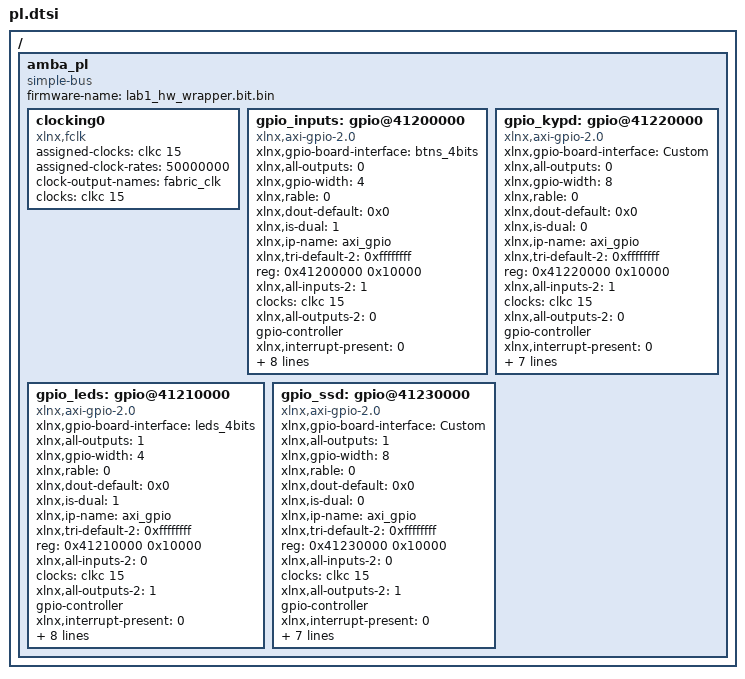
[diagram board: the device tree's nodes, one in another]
/ {
	amba_pl: amba_pl {
		ranges;
		compatible = "simple-bus";
		#address-cells = <1>;
		#size-cells = <1>;
		firmware-name = "lab1_hw_wrapper.bit.bin";
		clocking0: clocking0 {
			compatible = "xlnx,fclk";
			assigned-clocks = <&clkc 15>;
			assigned-clock-rates = <50000000>;
			#clock-cells = <0>;
			clock-output-names = "fabric_clk";
			clocks = <&clkc 15>;
		};
		gpio_inputs: gpio@41200000 {
			xlnx,gpio-board-interface = "btns_4bits";
			compatible = "xlnx,axi-gpio-2.0" , "xlnx,xps-gpio-1.00.a";
			xlnx,all-outputs = <0>;
			#gpio-cells = <2>;
			xlnx,gpio-width = <4>;
			xlnx,rable = <0>;
			xlnx,dout-default = <0x0>;
			xlnx,is-dual = <1>;
			xlnx,ip-name = "axi_gpio";
			xlnx,tri-default-2 = <0xffffffff>;
			reg = <0x41200000 0x10000>;
			xlnx,all-inputs-2 = <1>;
			clocks = <&clkc 15>;
			xlnx,all-outputs-2 = <0>;
			gpio-controller;
			xlnx,interrupt-present = <0>;
			xlnx,gpio2-board-interface = "sws_4bits";
			xlnx,edk-iptype = "PERIPHERAL";
			xlnx,dout-default-2 = <0x0>;
			status = "okay";
			xlnx,gpio2-width = <4>;
			clock-names = "s_axi_aclk";
			xlnx,use-board-flow;
			xlnx,tri-default = <0xffffffff>;
			xlnx,name = "gpio_inputs";
			xlnx,all-inputs = <1>;
		};
		gpio_kypd: gpio@41220000 {
			xlnx,gpio-board-interface = "Custom";
			compatible = "xlnx,axi-gpio-2.0" , "xlnx,xps-gpio-1.00.a";
			xlnx,all-outputs = <0>;
			#gpio-cells = <2>;
			xlnx,gpio-width = <8>;
			xlnx,rable = <0>;
			xlnx,dout-default = <0x0>;
			xlnx,is-dual = <0>;
			xlnx,ip-name = "axi_gpio";
			xlnx,tri-default-2 = <0xffffffff>;
			reg = <0x41220000 0x10000>;
			xlnx,all-inputs-2 = <1>;
			clocks = <&clkc 15>;
			xlnx,all-outputs-2 = <0>;
			gpio-controller;
			xlnx,interrupt-present = <0>;
			xlnx,gpio2-board-interface = "Custom";
			xlnx,edk-iptype = "PERIPHERAL";
			xlnx,dout-default-2 = <0x0>;
			status = "okay";
			xlnx,gpio2-width = <4>;
			clock-names = "s_axi_aclk";
			xlnx,tri-default = <0xffffffff>;
			xlnx,name = "gpio_kypd";
			xlnx,all-inputs = <0>;
		};
		gpio_leds: gpio@41210000 {
			xlnx,gpio-board-interface = "leds_4bits";
			compatible = "xlnx,axi-gpio-2.0" , "xlnx,xps-gpio-1.00.a";
			xlnx,all-outputs = <1>;
			#gpio-cells = <2>;
			xlnx,gpio-width = <4>;
			xlnx,rable = <0>;
			xlnx,dout-default = <0x0>;
			xlnx,is-dual = <1>;
			xlnx,ip-name = "axi_gpio";
			xlnx,tri-default-2 = <0xffffffff>;
			reg = <0x41210000 0x10000>;
			xlnx,all-inputs-2 = <0>;
			clocks = <&clkc 15>;
			xlnx,all-outputs-2 = <1>;
			gpio-controller;
			xlnx,interrupt-present = <0>;
			xlnx,gpio2-board-interface = "rgb_led";
			xlnx,edk-iptype = "PERIPHERAL";
			xlnx,dout-default-2 = <0x0>;
			status = "okay";
			xlnx,gpio2-width = <3>;
			clock-names = "s_axi_aclk";
			xlnx,use-board-flow;
			xlnx,tri-default = <0xffffffff>;
			xlnx,name = "gpio_leds";
			xlnx,all-inputs = <0>;
		};
		gpio_ssd: gpio@41230000 {
			xlnx,gpio-board-interface = "Custom";
			compatible = "xlnx,axi-gpio-2.0" , "xlnx,xps-gpio-1.00.a";
			xlnx,all-outputs = <1>;
			#gpio-cells = <2>;
			xlnx,gpio-width = <8>;
			xlnx,rable = <0>;
			xlnx,dout-default = <0x0>;
			xlnx,is-dual = <0>;
			xlnx,ip-name = "axi_gpio";
			xlnx,tri-default-2 = <0xffffffff>;
			reg = <0x41230000 0x10000>;
			xlnx,all-inputs-2 = <0>;
			clocks = <&clkc 15>;
			xlnx,all-outputs-2 = <1>;
			gpio-controller;
			xlnx,interrupt-present = <0>;
			xlnx,gpio2-board-interface = "Custom";
			xlnx,edk-iptype = "PERIPHERAL";
			xlnx,dout-default-2 = <0x0>;
			status = "okay";
			xlnx,gpio2-width = <6>;
			clock-names = "s_axi_aclk";
			xlnx,tri-default = <0xffffffff>;
			xlnx,name = "gpio_ssd";
			xlnx,all-inputs = <0>;
		};
	};
};
